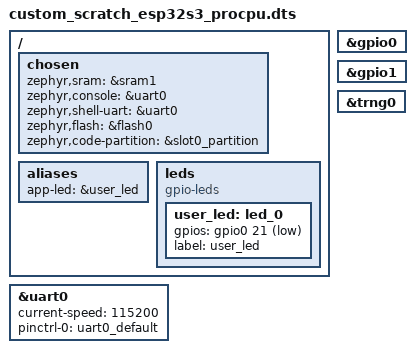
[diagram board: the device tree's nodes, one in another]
/dts-v1/;
#include <espressif/esp32s3/esp32s3_wroom_n8.dtsi>
#include <espressif/partitions_0x0_amp.dtsi>
#include "custom_scratch_esp32s3-pinctrl.dtsi"
#include <zephyr/dt-bindings/gpio/gpio.h>

/ {
	chosen {
		zephyr,sram = &sram1;
		zephyr,console = &uart0;
		zephyr,shell-uart = &uart0;
		zephyr,flash = &flash0;
		zephyr,code-partition = &slot0_partition;
	};

	aliases {
		app-led = &user_led;
	};

	leds {
	compatible = "gpio-leds";
	user_led: led_0 {
		gpios = <&gpio0 21 GPIO_ACTIVE_LOW>;
		label = "user_led";
		};
	};
};

&uart0 {
	status = "okay";
	current-speed = <115200>;
	pinctrl-0 = <&uart0_default>;
	pinctrl-names = "default";
};

&gpio0 { status = "okay"; };
&gpio1 { status = "okay"; };
&trng0 { status = "okay"; };
